VERSION "honda_bosch_a_radar -- 16-slot Bosch-A object bank (16 CAN-visible object slots, each a 4-frame main burst f0..f3 + one synchronized fine-angular companion frame). Hand-written (NOT generated by the opendbc generator pipeline). RANGE/AZIMUTH scaled companions are documentation-only; RadarInterface recomputes the physical values from RAW signals. f3 contains the two angular object bounds plus one matched edge-uncertainty magnitude; the companion frame contains the second matched edge-uncertainty magnitude and one still-unresolved auxiliary parameter. FRAME_IDX / LIFECYCLE_RAW are intentionally not named COUNTER."

NS_ :

BS_:

BU_: RADAR XXX

BO_ 640 BOSCH_A_S00_F0: 8 RADAR
 SG_ STATUS : 15|4@0+ (1,0) [0|15] "" XXX
 SG_ FRAME_IDX : 27|4@0+ (1,0) [0|15] "" XXX
 SG_ RANGE_RAW : 23|12@0+ (1,0) [0|4095] "" XXX
 SG_ RANGE : 23|12@0+ (0.05712,-3.0) [-3.0|231.7965] "m" XXX
 SG_ AZIMUTH_RAW : 39|11@0+ (1,0) [0|2047] "" XXX
 SG_ AZIMUTH_RAD : 39|11@0+ (0.00048828125,-0.5) [-0.5|0.49951171875] "rad" XXX
 SG_ AZIMUTH_DEG : 39|11@0+ (0.0279764548403722,-28.6478897565412) [-28.6478897565412|28.6199133017008] "deg" XXX

BO_ 641 BOSCH_A_S00_F1: 8 RADAR
 SG_ FRAME_IDX : 28|4@0+ (1,0) [0|15] "" XXX

BO_ 642 BOSCH_A_S00_F2: 8 RADAR
 SG_ FRAME_IDX : 11|4@0+ (1,0) [0|15] "" XXX
 SG_ LIFECYCLE_RAW : 7|12@0+ (1,0) [0|4095] "" XXX

BO_ 643 BOSCH_A_S00_F3: 8 RADAR
 SG_ AZIMUTH_EDGE_A_RAW : 7|11@0+ (1,0) [0|2047] "" XXX
 SG_ AZIMUTH_EDGE_A_RAD : 7|11@0+ (0.00048828125,-0.5) [-0.5|0.49951171875] "rad" XXX
 SG_ FRAME_IDX : 12|4@0+ (1,0) [0|15] "" XXX
 SG_ AZIMUTH_EDGE_B_RAW : 23|11@0+ (1,0) [0|2047] "" XXX
 SG_ AZIMUTH_EDGE_B_RAD : 23|11@0+ (0.00048828125,-0.5) [-0.5|0.49951171875] "rad" XXX
 SG_ AZIMUTH_EDGE_SIGMA_A_RAW : 39|10@0+ (1,0) [0|1023] "" XXX
 SG_ TRACK_ID : 55|8@0+ (1,0) [0|255] "" XXX

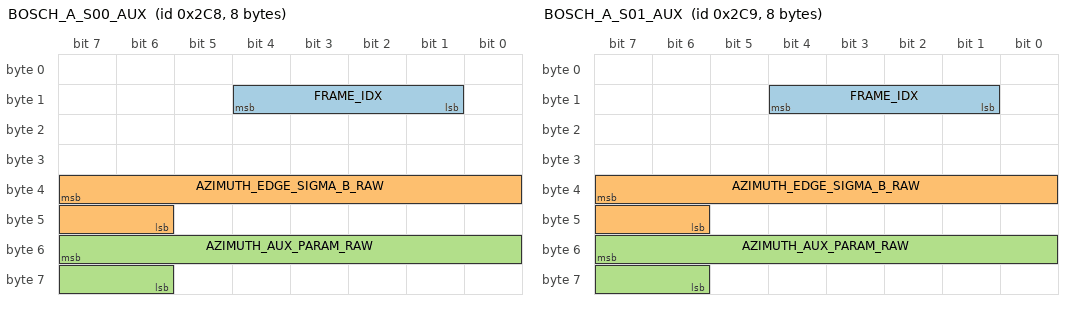
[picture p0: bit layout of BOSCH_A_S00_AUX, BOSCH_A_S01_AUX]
BO_ 712 BOSCH_A_S00_AUX: 8 RADAR
 SG_ FRAME_IDX : 12|4@0+ (1,0) [0|15] "" XXX
 SG_ AZIMUTH_EDGE_SIGMA_B_RAW : 39|10@0+ (1,0) [0|1023] "" XXX
 SG_ AZIMUTH_AUX_PARAM_RAW : 55|10@0+ (1,0) [0|1023] "" XXX

BO_ 644 BOSCH_A_S01_F0: 8 RADAR
 SG_ STATUS : 15|4@0+ (1,0) [0|15] "" XXX
 SG_ FRAME_IDX : 27|4@0+ (1,0) [0|15] "" XXX
 SG_ RANGE_RAW : 23|12@0+ (1,0) [0|4095] "" XXX
 SG_ RANGE : 23|12@0+ (0.05712,-3.0) [-3.0|231.7965] "m" XXX
 SG_ AZIMUTH_RAW : 39|11@0+ (1,0) [0|2047] "" XXX
 SG_ AZIMUTH_RAD : 39|11@0+ (0.00048828125,-0.5) [-0.5|0.49951171875] "rad" XXX
 SG_ AZIMUTH_DEG : 39|11@0+ (0.0279764548403722,-28.6478897565412) [-28.6478897565412|28.6199133017008] "deg" XXX

BO_ 645 BOSCH_A_S01_F1: 8 RADAR
 SG_ FRAME_IDX : 28|4@0+ (1,0) [0|15] "" XXX

BO_ 646 BOSCH_A_S01_F2: 8 RADAR
 SG_ FRAME_IDX : 11|4@0+ (1,0) [0|15] "" XXX
 SG_ LIFECYCLE_RAW : 7|12@0+ (1,0) [0|4095] "" XXX

BO_ 647 BOSCH_A_S01_F3: 8 RADAR
 SG_ AZIMUTH_EDGE_A_RAW : 7|11@0+ (1,0) [0|2047] "" XXX
 SG_ AZIMUTH_EDGE_A_RAD : 7|11@0+ (0.00048828125,-0.5) [-0.5|0.49951171875] "rad" XXX
 SG_ FRAME_IDX : 12|4@0+ (1,0) [0|15] "" XXX
 SG_ AZIMUTH_EDGE_B_RAW : 23|11@0+ (1,0) [0|2047] "" XXX
 SG_ AZIMUTH_EDGE_B_RAD : 23|11@0+ (0.00048828125,-0.5) [-0.5|0.49951171875] "rad" XXX
 SG_ AZIMUTH_EDGE_SIGMA_A_RAW : 39|10@0+ (1,0) [0|1023] "" XXX
 SG_ TRACK_ID : 55|8@0+ (1,0) [0|255] "" XXX

BO_ 713 BOSCH_A_S01_AUX: 8 RADAR
 SG_ FRAME_IDX : 12|4@0+ (1,0) [0|15] "" XXX
 SG_ AZIMUTH_EDGE_SIGMA_B_RAW : 39|10@0+ (1,0) [0|1023] "" XXX
 SG_ AZIMUTH_AUX_PARAM_RAW : 55|10@0+ (1,0) [0|1023] "" XXX

BO_ 648 BOSCH_A_S02_F0: 8 RADAR
 SG_ STATUS : 15|4@0+ (1,0) [0|15] "" XXX
 SG_ FRAME_IDX : 27|4@0+ (1,0) [0|15] "" XXX
 SG_ RANGE_RAW : 23|12@0+ (1,0) [0|4095] "" XXX
 SG_ RANGE : 23|12@0+ (0.05712,-3.0) [-3.0|231.7965] "m" XXX
 SG_ AZIMUTH_RAW : 39|11@0+ (1,0) [0|2047] "" XXX
 SG_ AZIMUTH_RAD : 39|11@0+ (0.00048828125,-0.5) [-0.5|0.49951171875] "rad" XXX
 SG_ AZIMUTH_DEG : 39|11@0+ (0.0279764548403722,-28.6478897565412) [-28.6478897565412|28.6199133017008] "deg" XXX

BO_ 649 BOSCH_A_S02_F1: 8 RADAR
 SG_ FRAME_IDX : 28|4@0+ (1,0) [0|15] "" XXX

BO_ 650 BOSCH_A_S02_F2: 8 RADAR
 SG_ FRAME_IDX : 11|4@0+ (1,0) [0|15] "" XXX
 SG_ LIFECYCLE_RAW : 7|12@0+ (1,0) [0|4095] "" XXX

BO_ 651 BOSCH_A_S02_F3: 8 RADAR
 SG_ AZIMUTH_EDGE_A_RAW : 7|11@0+ (1,0) [0|2047] "" XXX
 SG_ AZIMUTH_EDGE_A_RAD : 7|11@0+ (0.00048828125,-0.5) [-0.5|0.49951171875] "rad" XXX
 SG_ FRAME_IDX : 12|4@0+ (1,0) [0|15] "" XXX
 SG_ AZIMUTH_EDGE_B_RAW : 23|11@0+ (1,0) [0|2047] "" XXX
 SG_ AZIMUTH_EDGE_B_RAD : 23|11@0+ (0.00048828125,-0.5) [-0.5|0.49951171875] "rad" XXX
 SG_ AZIMUTH_EDGE_SIGMA_A_RAW : 39|10@0+ (1,0) [0|1023] "" XXX
 SG_ TRACK_ID : 55|8@0+ (1,0) [0|255] "" XXX

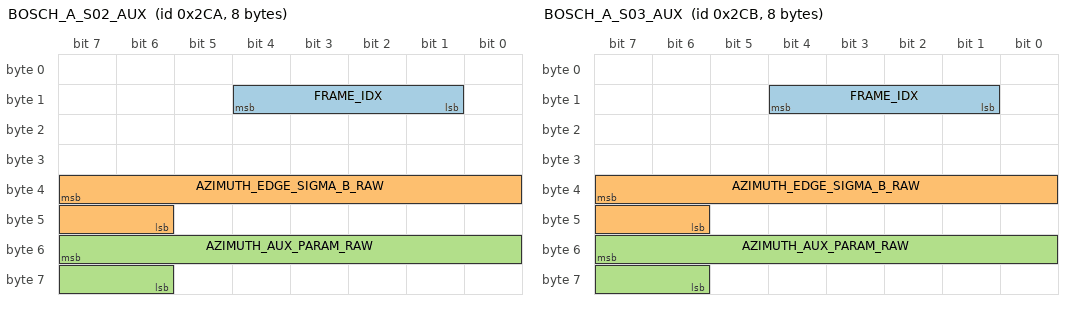
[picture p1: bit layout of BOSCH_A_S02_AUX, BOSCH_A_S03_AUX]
BO_ 714 BOSCH_A_S02_AUX: 8 RADAR
 SG_ FRAME_IDX : 12|4@0+ (1,0) [0|15] "" XXX
 SG_ AZIMUTH_EDGE_SIGMA_B_RAW : 39|10@0+ (1,0) [0|1023] "" XXX
 SG_ AZIMUTH_AUX_PARAM_RAW : 55|10@0+ (1,0) [0|1023] "" XXX

BO_ 652 BOSCH_A_S03_F0: 8 RADAR
 SG_ STATUS : 15|4@0+ (1,0) [0|15] "" XXX
 SG_ FRAME_IDX : 27|4@0+ (1,0) [0|15] "" XXX
 SG_ RANGE_RAW : 23|12@0+ (1,0) [0|4095] "" XXX
 SG_ RANGE : 23|12@0+ (0.05712,-3.0) [-3.0|231.7965] "m" XXX
 SG_ AZIMUTH_RAW : 39|11@0+ (1,0) [0|2047] "" XXX
 SG_ AZIMUTH_RAD : 39|11@0+ (0.00048828125,-0.5) [-0.5|0.49951171875] "rad" XXX
 SG_ AZIMUTH_DEG : 39|11@0+ (0.0279764548403722,-28.6478897565412) [-28.6478897565412|28.6199133017008] "deg" XXX

BO_ 653 BOSCH_A_S03_F1: 8 RADAR
 SG_ FRAME_IDX : 28|4@0+ (1,0) [0|15] "" XXX

BO_ 654 BOSCH_A_S03_F2: 8 RADAR
 SG_ FRAME_IDX : 11|4@0+ (1,0) [0|15] "" XXX
 SG_ LIFECYCLE_RAW : 7|12@0+ (1,0) [0|4095] "" XXX

BO_ 655 BOSCH_A_S03_F3: 8 RADAR
 SG_ AZIMUTH_EDGE_A_RAW : 7|11@0+ (1,0) [0|2047] "" XXX
 SG_ AZIMUTH_EDGE_A_RAD : 7|11@0+ (0.00048828125,-0.5) [-0.5|0.49951171875] "rad" XXX
 SG_ FRAME_IDX : 12|4@0+ (1,0) [0|15] "" XXX
 SG_ AZIMUTH_EDGE_B_RAW : 23|11@0+ (1,0) [0|2047] "" XXX
 SG_ AZIMUTH_EDGE_B_RAD : 23|11@0+ (0.00048828125,-0.5) [-0.5|0.49951171875] "rad" XXX
 SG_ AZIMUTH_EDGE_SIGMA_A_RAW : 39|10@0+ (1,0) [0|1023] "" XXX
 SG_ TRACK_ID : 55|8@0+ (1,0) [0|255] "" XXX

BO_ 715 BOSCH_A_S03_AUX: 8 RADAR
 SG_ FRAME_IDX : 12|4@0+ (1,0) [0|15] "" XXX
 SG_ AZIMUTH_EDGE_SIGMA_B_RAW : 39|10@0+ (1,0) [0|1023] "" XXX
 SG_ AZIMUTH_AUX_PARAM_RAW : 55|10@0+ (1,0) [0|1023] "" XXX

BO_ 720 BOSCH_A_S04_F0: 8 RADAR
 SG_ STATUS : 15|4@0+ (1,0) [0|15] "" XXX
 SG_ FRAME_IDX : 27|4@0+ (1,0) [0|15] "" XXX
 SG_ RANGE_RAW : 23|12@0+ (1,0) [0|4095] "" XXX
 SG_ RANGE : 23|12@0+ (0.05712,-3.0) [-3.0|231.7965] "m" XXX
 SG_ AZIMUTH_RAW : 39|11@0+ (1,0) [0|2047] "" XXX
 SG_ AZIMUTH_RAD : 39|11@0+ (0.00048828125,-0.5) [-0.5|0.49951171875] "rad" XXX
 SG_ AZIMUTH_DEG : 39|11@0+ (0.0279764548403722,-28.6478897565412) [-28.6478897565412|28.6199133017008] "deg" XXX

BO_ 721 BOSCH_A_S04_F1: 8 RADAR
 SG_ FRAME_IDX : 28|4@0+ (1,0) [0|15] "" XXX

BO_ 722 BOSCH_A_S04_F2: 8 RADAR
 SG_ FRAME_IDX : 11|4@0+ (1,0) [0|15] "" XXX
 SG_ LIFECYCLE_RAW : 7|12@0+ (1,0) [0|4095] "" XXX

BO_ 723 BOSCH_A_S04_F3: 8 RADAR
 SG_ AZIMUTH_EDGE_A_RAW : 7|11@0+ (1,0) [0|2047] "" XXX
 SG_ AZIMUTH_EDGE_A_RAD : 7|11@0+ (0.00048828125,-0.5) [-0.5|0.49951171875] "rad" XXX
 SG_ FRAME_IDX : 12|4@0+ (1,0) [0|15] "" XXX
 SG_ AZIMUTH_EDGE_B_RAW : 23|11@0+ (1,0) [0|2047] "" XXX
 SG_ AZIMUTH_EDGE_B_RAD : 23|11@0+ (0.00048828125,-0.5) [-0.5|0.49951171875] "rad" XXX
 SG_ AZIMUTH_EDGE_SIGMA_A_RAW : 39|10@0+ (1,0) [0|1023] "" XXX
 SG_ TRACK_ID : 55|8@0+ (1,0) [0|255] "" XXX

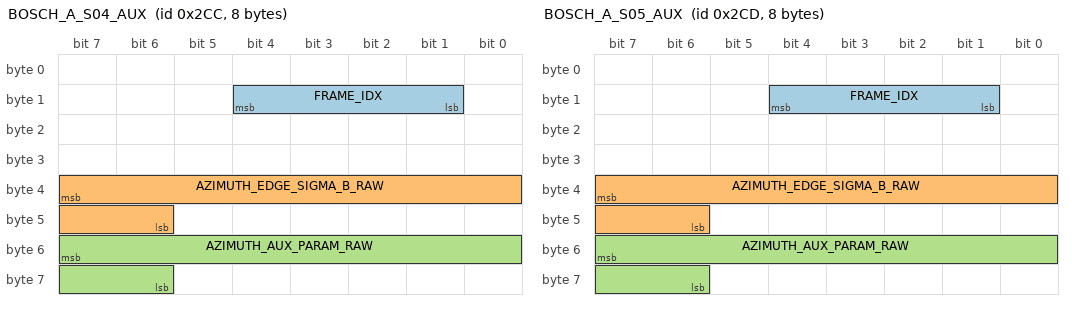
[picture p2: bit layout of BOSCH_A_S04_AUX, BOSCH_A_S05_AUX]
BO_ 716 BOSCH_A_S04_AUX: 8 RADAR
 SG_ FRAME_IDX : 12|4@0+ (1,0) [0|15] "" XXX
 SG_ AZIMUTH_EDGE_SIGMA_B_RAW : 39|10@0+ (1,0) [0|1023] "" XXX
 SG_ AZIMUTH_AUX_PARAM_RAW : 55|10@0+ (1,0) [0|1023] "" XXX

BO_ 724 BOSCH_A_S05_F0: 8 RADAR
 SG_ STATUS : 15|4@0+ (1,0) [0|15] "" XXX
 SG_ FRAME_IDX : 27|4@0+ (1,0) [0|15] "" XXX
 SG_ RANGE_RAW : 23|12@0+ (1,0) [0|4095] "" XXX
 SG_ RANGE : 23|12@0+ (0.05712,-3.0) [-3.0|231.7965] "m" XXX
 SG_ AZIMUTH_RAW : 39|11@0+ (1,0) [0|2047] "" XXX
 SG_ AZIMUTH_RAD : 39|11@0+ (0.00048828125,-0.5) [-0.5|0.49951171875] "rad" XXX
 SG_ AZIMUTH_DEG : 39|11@0+ (0.0279764548403722,-28.6478897565412) [-28.6478897565412|28.6199133017008] "deg" XXX

BO_ 725 BOSCH_A_S05_F1: 8 RADAR
 SG_ FRAME_IDX : 28|4@0+ (1,0) [0|15] "" XXX

BO_ 726 BOSCH_A_S05_F2: 8 RADAR
 SG_ FRAME_IDX : 11|4@0+ (1,0) [0|15] "" XXX
 SG_ LIFECYCLE_RAW : 7|12@0+ (1,0) [0|4095] "" XXX

BO_ 727 BOSCH_A_S05_F3: 8 RADAR
 SG_ AZIMUTH_EDGE_A_RAW : 7|11@0+ (1,0) [0|2047] "" XXX
 SG_ AZIMUTH_EDGE_A_RAD : 7|11@0+ (0.00048828125,-0.5) [-0.5|0.49951171875] "rad" XXX
 SG_ FRAME_IDX : 12|4@0+ (1,0) [0|15] "" XXX
 SG_ AZIMUTH_EDGE_B_RAW : 23|11@0+ (1,0) [0|2047] "" XXX
 SG_ AZIMUTH_EDGE_B_RAD : 23|11@0+ (0.00048828125,-0.5) [-0.5|0.49951171875] "rad" XXX
 SG_ AZIMUTH_EDGE_SIGMA_A_RAW : 39|10@0+ (1,0) [0|1023] "" XXX
 SG_ TRACK_ID : 55|8@0+ (1,0) [0|255] "" XXX

BO_ 717 BOSCH_A_S05_AUX: 8 RADAR
 SG_ FRAME_IDX : 12|4@0+ (1,0) [0|15] "" XXX
 SG_ AZIMUTH_EDGE_SIGMA_B_RAW : 39|10@0+ (1,0) [0|1023] "" XXX
 SG_ AZIMUTH_AUX_PARAM_RAW : 55|10@0+ (1,0) [0|1023] "" XXX

BO_ 728 BOSCH_A_S06_F0: 8 RADAR
 SG_ STATUS : 15|4@0+ (1,0) [0|15] "" XXX
 SG_ FRAME_IDX : 27|4@0+ (1,0) [0|15] "" XXX
 SG_ RANGE_RAW : 23|12@0+ (1,0) [0|4095] "" XXX
 SG_ RANGE : 23|12@0+ (0.05712,-3.0) [-3.0|231.7965] "m" XXX
 SG_ AZIMUTH_RAW : 39|11@0+ (1,0) [0|2047] "" XXX
 SG_ AZIMUTH_RAD : 39|11@0+ (0.00048828125,-0.5) [-0.5|0.49951171875] "rad" XXX
 SG_ AZIMUTH_DEG : 39|11@0+ (0.0279764548403722,-28.6478897565412) [-28.6478897565412|28.6199133017008] "deg" XXX

BO_ 729 BOSCH_A_S06_F1: 8 RADAR
 SG_ FRAME_IDX : 28|4@0+ (1,0) [0|15] "" XXX

BO_ 730 BOSCH_A_S06_F2: 8 RADAR
 SG_ FRAME_IDX : 11|4@0+ (1,0) [0|15] "" XXX
 SG_ LIFECYCLE_RAW : 7|12@0+ (1,0) [0|4095] "" XXX

BO_ 731 BOSCH_A_S06_F3: 8 RADAR
 SG_ AZIMUTH_EDGE_A_RAW : 7|11@0+ (1,0) [0|2047] "" XXX
 SG_ AZIMUTH_EDGE_A_RAD : 7|11@0+ (0.00048828125,-0.5) [-0.5|0.49951171875] "rad" XXX
 SG_ FRAME_IDX : 12|4@0+ (1,0) [0|15] "" XXX
 SG_ AZIMUTH_EDGE_B_RAW : 23|11@0+ (1,0) [0|2047] "" XXX
 SG_ AZIMUTH_EDGE_B_RAD : 23|11@0+ (0.00048828125,-0.5) [-0.5|0.49951171875] "rad" XXX
 SG_ AZIMUTH_EDGE_SIGMA_A_RAW : 39|10@0+ (1,0) [0|1023] "" XXX
 SG_ TRACK_ID : 55|8@0+ (1,0) [0|255] "" XXX

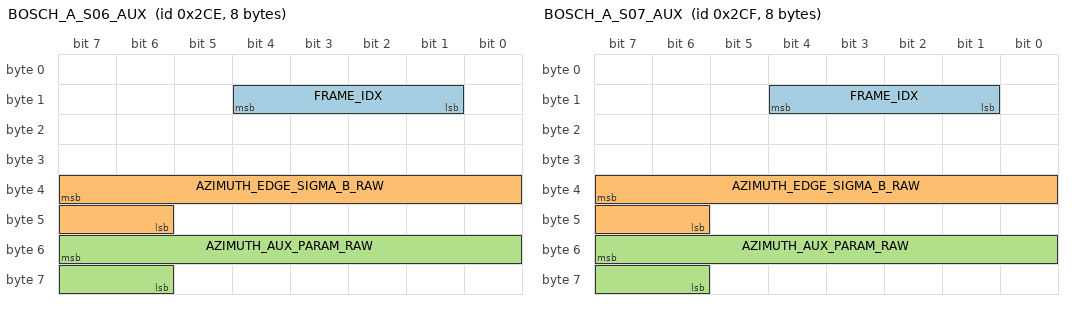
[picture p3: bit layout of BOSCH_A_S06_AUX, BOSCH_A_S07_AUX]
BO_ 718 BOSCH_A_S06_AUX: 8 RADAR
 SG_ FRAME_IDX : 12|4@0+ (1,0) [0|15] "" XXX
 SG_ AZIMUTH_EDGE_SIGMA_B_RAW : 39|10@0+ (1,0) [0|1023] "" XXX
 SG_ AZIMUTH_AUX_PARAM_RAW : 55|10@0+ (1,0) [0|1023] "" XXX

BO_ 732 BOSCH_A_S07_F0: 8 RADAR
 SG_ STATUS : 15|4@0+ (1,0) [0|15] "" XXX
 SG_ FRAME_IDX : 27|4@0+ (1,0) [0|15] "" XXX
 SG_ RANGE_RAW : 23|12@0+ (1,0) [0|4095] "" XXX
 SG_ RANGE : 23|12@0+ (0.05712,-3.0) [-3.0|231.7965] "m" XXX
 SG_ AZIMUTH_RAW : 39|11@0+ (1,0) [0|2047] "" XXX
 SG_ AZIMUTH_RAD : 39|11@0+ (0.00048828125,-0.5) [-0.5|0.49951171875] "rad" XXX
 SG_ AZIMUTH_DEG : 39|11@0+ (0.0279764548403722,-28.6478897565412) [-28.6478897565412|28.6199133017008] "deg" XXX

BO_ 733 BOSCH_A_S07_F1: 8 RADAR
 SG_ FRAME_IDX : 28|4@0+ (1,0) [0|15] "" XXX

BO_ 734 BOSCH_A_S07_F2: 8 RADAR
 SG_ FRAME_IDX : 11|4@0+ (1,0) [0|15] "" XXX
 SG_ LIFECYCLE_RAW : 7|12@0+ (1,0) [0|4095] "" XXX

BO_ 735 BOSCH_A_S07_F3: 8 RADAR
 SG_ AZIMUTH_EDGE_A_RAW : 7|11@0+ (1,0) [0|2047] "" XXX
 SG_ AZIMUTH_EDGE_A_RAD : 7|11@0+ (0.00048828125,-0.5) [-0.5|0.49951171875] "rad" XXX
 SG_ FRAME_IDX : 12|4@0+ (1,0) [0|15] "" XXX
 SG_ AZIMUTH_EDGE_B_RAW : 23|11@0+ (1,0) [0|2047] "" XXX
 SG_ AZIMUTH_EDGE_B_RAD : 23|11@0+ (0.00048828125,-0.5) [-0.5|0.49951171875] "rad" XXX
 SG_ AZIMUTH_EDGE_SIGMA_A_RAW : 39|10@0+ (1,0) [0|1023] "" XXX
 SG_ TRACK_ID : 55|8@0+ (1,0) [0|255] "" XXX

BO_ 719 BOSCH_A_S07_AUX: 8 RADAR
 SG_ FRAME_IDX : 12|4@0+ (1,0) [0|15] "" XXX
 SG_ AZIMUTH_EDGE_SIGMA_B_RAW : 39|10@0+ (1,0) [0|1023] "" XXX
 SG_ AZIMUTH_AUX_PARAM_RAW : 55|10@0+ (1,0) [0|1023] "" XXX

BO_ 736 BOSCH_A_S08_F0: 8 RADAR
 SG_ STATUS : 15|4@0+ (1,0) [0|15] "" XXX
 SG_ FRAME_IDX : 27|4@0+ (1,0) [0|15] "" XXX
 SG_ RANGE_RAW : 23|12@0+ (1,0) [0|4095] "" XXX
 SG_ RANGE : 23|12@0+ (0.05712,-3.0) [-3.0|231.7965] "m" XXX
 SG_ AZIMUTH_RAW : 39|11@0+ (1,0) [0|2047] "" XXX
 SG_ AZIMUTH_RAD : 39|11@0+ (0.00048828125,-0.5) [-0.5|0.49951171875] "rad" XXX
 SG_ AZIMUTH_DEG : 39|11@0+ (0.0279764548403722,-28.6478897565412) [-28.6478897565412|28.6199133017008] "deg" XXX

BO_ 737 BOSCH_A_S08_F1: 8 RADAR
 SG_ FRAME_IDX : 28|4@0+ (1,0) [0|15] "" XXX

BO_ 738 BOSCH_A_S08_F2: 8 RADAR
 SG_ FRAME_IDX : 11|4@0+ (1,0) [0|15] "" XXX
 SG_ LIFECYCLE_RAW : 7|12@0+ (1,0) [0|4095] "" XXX

BO_ 739 BOSCH_A_S08_F3: 8 RADAR
 SG_ AZIMUTH_EDGE_A_RAW : 7|11@0+ (1,0) [0|2047] "" XXX
 SG_ AZIMUTH_EDGE_A_RAD : 7|11@0+ (0.00048828125,-0.5) [-0.5|0.49951171875] "rad" XXX
 SG_ FRAME_IDX : 12|4@0+ (1,0) [0|15] "" XXX
 SG_ AZIMUTH_EDGE_B_RAW : 23|11@0+ (1,0) [0|2047] "" XXX
 SG_ AZIMUTH_EDGE_B_RAD : 23|11@0+ (0.00048828125,-0.5) [-0.5|0.49951171875] "rad" XXX
 SG_ AZIMUTH_EDGE_SIGMA_A_RAW : 39|10@0+ (1,0) [0|1023] "" XXX
 SG_ TRACK_ID : 55|8@0+ (1,0) [0|255] "" XXX

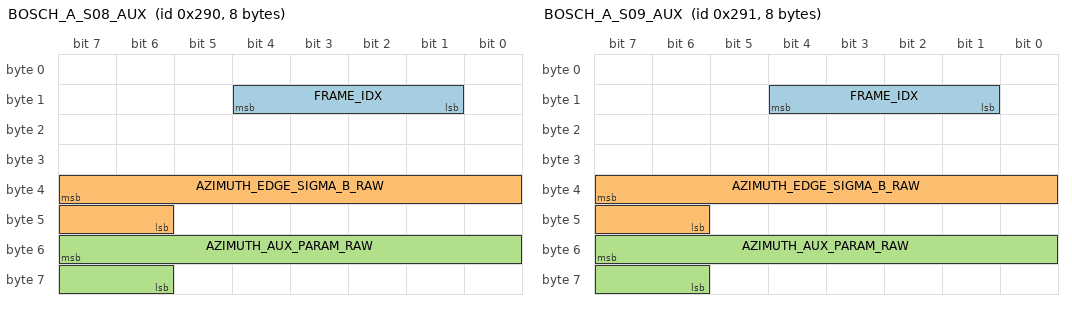
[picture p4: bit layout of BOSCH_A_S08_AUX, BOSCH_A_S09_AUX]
BO_ 656 BOSCH_A_S08_AUX: 8 RADAR
 SG_ FRAME_IDX : 12|4@0+ (1,0) [0|15] "" XXX
 SG_ AZIMUTH_EDGE_SIGMA_B_RAW : 39|10@0+ (1,0) [0|1023] "" XXX
 SG_ AZIMUTH_AUX_PARAM_RAW : 55|10@0+ (1,0) [0|1023] "" XXX

BO_ 740 BOSCH_A_S09_F0: 8 RADAR
 SG_ STATUS : 15|4@0+ (1,0) [0|15] "" XXX
 SG_ FRAME_IDX : 27|4@0+ (1,0) [0|15] "" XXX
 SG_ RANGE_RAW : 23|12@0+ (1,0) [0|4095] "" XXX
 SG_ RANGE : 23|12@0+ (0.05712,-3.0) [-3.0|231.7965] "m" XXX
 SG_ AZIMUTH_RAW : 39|11@0+ (1,0) [0|2047] "" XXX
 SG_ AZIMUTH_RAD : 39|11@0+ (0.00048828125,-0.5) [-0.5|0.49951171875] "rad" XXX
 SG_ AZIMUTH_DEG : 39|11@0+ (0.0279764548403722,-28.6478897565412) [-28.6478897565412|28.6199133017008] "deg" XXX

BO_ 741 BOSCH_A_S09_F1: 8 RADAR
 SG_ FRAME_IDX : 28|4@0+ (1,0) [0|15] "" XXX

BO_ 742 BOSCH_A_S09_F2: 8 RADAR
 SG_ FRAME_IDX : 11|4@0+ (1,0) [0|15] "" XXX
 SG_ LIFECYCLE_RAW : 7|12@0+ (1,0) [0|4095] "" XXX

BO_ 743 BOSCH_A_S09_F3: 8 RADAR
 SG_ AZIMUTH_EDGE_A_RAW : 7|11@0+ (1,0) [0|2047] "" XXX
 SG_ AZIMUTH_EDGE_A_RAD : 7|11@0+ (0.00048828125,-0.5) [-0.5|0.49951171875] "rad" XXX
 SG_ FRAME_IDX : 12|4@0+ (1,0) [0|15] "" XXX
 SG_ AZIMUTH_EDGE_B_RAW : 23|11@0+ (1,0) [0|2047] "" XXX
 SG_ AZIMUTH_EDGE_B_RAD : 23|11@0+ (0.00048828125,-0.5) [-0.5|0.49951171875] "rad" XXX
 SG_ AZIMUTH_EDGE_SIGMA_A_RAW : 39|10@0+ (1,0) [0|1023] "" XXX
 SG_ TRACK_ID : 55|8@0+ (1,0) [0|255] "" XXX

BO_ 657 BOSCH_A_S09_AUX: 8 RADAR
 SG_ FRAME_IDX : 12|4@0+ (1,0) [0|15] "" XXX
 SG_ AZIMUTH_EDGE_SIGMA_B_RAW : 39|10@0+ (1,0) [0|1023] "" XXX
 SG_ AZIMUTH_AUX_PARAM_RAW : 55|10@0+ (1,0) [0|1023] "" XXX

BO_ 744 BOSCH_A_S10_F0: 8 RADAR
 SG_ STATUS : 15|4@0+ (1,0) [0|15] "" XXX
 SG_ FRAME_IDX : 27|4@0+ (1,0) [0|15] "" XXX
 SG_ RANGE_RAW : 23|12@0+ (1,0) [0|4095] "" XXX
 SG_ RANGE : 23|12@0+ (0.05712,-3.0) [-3.0|231.7965] "m" XXX
 SG_ AZIMUTH_RAW : 39|11@0+ (1,0) [0|2047] "" XXX
 SG_ AZIMUTH_RAD : 39|11@0+ (0.00048828125,-0.5) [-0.5|0.49951171875] "rad" XXX
 SG_ AZIMUTH_DEG : 39|11@0+ (0.0279764548403722,-28.6478897565412) [-28.6478897565412|28.6199133017008] "deg" XXX

BO_ 745 BOSCH_A_S10_F1: 8 RADAR
 SG_ FRAME_IDX : 28|4@0+ (1,0) [0|15] "" XXX

BO_ 746 BOSCH_A_S10_F2: 8 RADAR
 SG_ FRAME_IDX : 11|4@0+ (1,0) [0|15] "" XXX
 SG_ LIFECYCLE_RAW : 7|12@0+ (1,0) [0|4095] "" XXX

BO_ 747 BOSCH_A_S10_F3: 8 RADAR
 SG_ AZIMUTH_EDGE_A_RAW : 7|11@0+ (1,0) [0|2047] "" XXX
 SG_ AZIMUTH_EDGE_A_RAD : 7|11@0+ (0.00048828125,-0.5) [-0.5|0.49951171875] "rad" XXX
 SG_ FRAME_IDX : 12|4@0+ (1,0) [0|15] "" XXX
 SG_ AZIMUTH_EDGE_B_RAW : 23|11@0+ (1,0) [0|2047] "" XXX
 SG_ AZIMUTH_EDGE_B_RAD : 23|11@0+ (0.00048828125,-0.5) [-0.5|0.49951171875] "rad" XXX
 SG_ AZIMUTH_EDGE_SIGMA_A_RAW : 39|10@0+ (1,0) [0|1023] "" XXX
 SG_ TRACK_ID : 55|8@0+ (1,0) [0|255] "" XXX

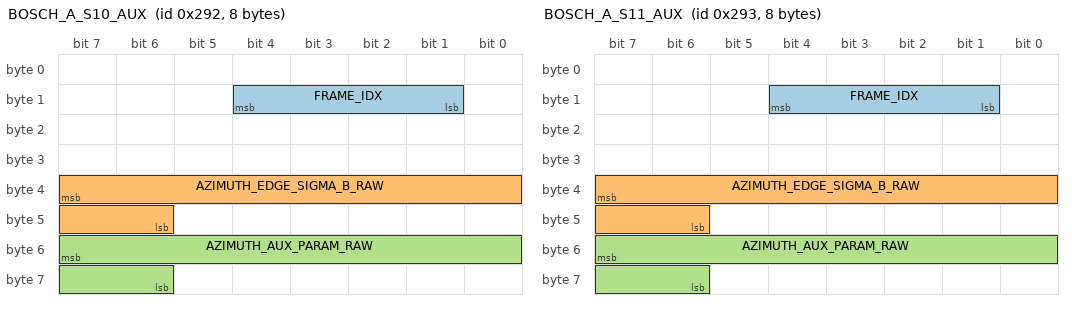
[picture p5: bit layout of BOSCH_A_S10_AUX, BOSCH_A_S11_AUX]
BO_ 658 BOSCH_A_S10_AUX: 8 RADAR
 SG_ FRAME_IDX : 12|4@0+ (1,0) [0|15] "" XXX
 SG_ AZIMUTH_EDGE_SIGMA_B_RAW : 39|10@0+ (1,0) [0|1023] "" XXX
 SG_ AZIMUTH_AUX_PARAM_RAW : 55|10@0+ (1,0) [0|1023] "" XXX

BO_ 748 BOSCH_A_S11_F0: 8 RADAR
 SG_ STATUS : 15|4@0+ (1,0) [0|15] "" XXX
 SG_ FRAME_IDX : 27|4@0+ (1,0) [0|15] "" XXX
 SG_ RANGE_RAW : 23|12@0+ (1,0) [0|4095] "" XXX
 SG_ RANGE : 23|12@0+ (0.05712,-3.0) [-3.0|231.7965] "m" XXX
 SG_ AZIMUTH_RAW : 39|11@0+ (1,0) [0|2047] "" XXX
 SG_ AZIMUTH_RAD : 39|11@0+ (0.00048828125,-0.5) [-0.5|0.49951171875] "rad" XXX
 SG_ AZIMUTH_DEG : 39|11@0+ (0.0279764548403722,-28.6478897565412) [-28.6478897565412|28.6199133017008] "deg" XXX

BO_ 749 BOSCH_A_S11_F1: 8 RADAR
 SG_ FRAME_IDX : 28|4@0+ (1,0) [0|15] "" XXX

BO_ 750 BOSCH_A_S11_F2: 8 RADAR
 SG_ FRAME_IDX : 11|4@0+ (1,0) [0|15] "" XXX
 SG_ LIFECYCLE_RAW : 7|12@0+ (1,0) [0|4095] "" XXX

BO_ 751 BOSCH_A_S11_F3: 8 RADAR
 SG_ AZIMUTH_EDGE_A_RAW : 7|11@0+ (1,0) [0|2047] "" XXX
 SG_ AZIMUTH_EDGE_A_RAD : 7|11@0+ (0.00048828125,-0.5) [-0.5|0.49951171875] "rad" XXX
 SG_ FRAME_IDX : 12|4@0+ (1,0) [0|15] "" XXX
 SG_ AZIMUTH_EDGE_B_RAW : 23|11@0+ (1,0) [0|2047] "" XXX
 SG_ AZIMUTH_EDGE_B_RAD : 23|11@0+ (0.00048828125,-0.5) [-0.5|0.49951171875] "rad" XXX
 SG_ AZIMUTH_EDGE_SIGMA_A_RAW : 39|10@0+ (1,0) [0|1023] "" XXX
 SG_ TRACK_ID : 55|8@0+ (1,0) [0|255] "" XXX

BO_ 659 BOSCH_A_S11_AUX: 8 RADAR
 SG_ FRAME_IDX : 12|4@0+ (1,0) [0|15] "" XXX
 SG_ AZIMUTH_EDGE_SIGMA_B_RAW : 39|10@0+ (1,0) [0|1023] "" XXX
 SG_ AZIMUTH_AUX_PARAM_RAW : 55|10@0+ (1,0) [0|1023] "" XXX

BO_ 752 BOSCH_A_S12_F0: 8 RADAR
 SG_ STATUS : 15|4@0+ (1,0) [0|15] "" XXX
 SG_ FRAME_IDX : 27|4@0+ (1,0) [0|15] "" XXX
 SG_ RANGE_RAW : 23|12@0+ (1,0) [0|4095] "" XXX
 SG_ RANGE : 23|12@0+ (0.05712,-3.0) [-3.0|231.7965] "m" XXX
 SG_ AZIMUTH_RAW : 39|11@0+ (1,0) [0|2047] "" XXX
 SG_ AZIMUTH_RAD : 39|11@0+ (0.00048828125,-0.5) [-0.5|0.49951171875] "rad" XXX
 SG_ AZIMUTH_DEG : 39|11@0+ (0.0279764548403722,-28.6478897565412) [-28.6478897565412|28.6199133017008] "deg" XXX

BO_ 753 BOSCH_A_S12_F1: 8 RADAR
 SG_ FRAME_IDX : 28|4@0+ (1,0) [0|15] "" XXX

BO_ 754 BOSCH_A_S12_F2: 8 RADAR
 SG_ FRAME_IDX : 11|4@0+ (1,0) [0|15] "" XXX
 SG_ LIFECYCLE_RAW : 7|12@0+ (1,0) [0|4095] "" XXX

BO_ 755 BOSCH_A_S12_F3: 8 RADAR
 SG_ AZIMUTH_EDGE_A_RAW : 7|11@0+ (1,0) [0|2047] "" XXX
 SG_ AZIMUTH_EDGE_A_RAD : 7|11@0+ (0.00048828125,-0.5) [-0.5|0.49951171875] "rad" XXX
 SG_ FRAME_IDX : 12|4@0+ (1,0) [0|15] "" XXX
 SG_ AZIMUTH_EDGE_B_RAW : 23|11@0+ (1,0) [0|2047] "" XXX
 SG_ AZIMUTH_EDGE_B_RAD : 23|11@0+ (0.00048828125,-0.5) [-0.5|0.49951171875] "rad" XXX
 SG_ AZIMUTH_EDGE_SIGMA_A_RAW : 39|10@0+ (1,0) [0|1023] "" XXX
 SG_ TRACK_ID : 55|8@0+ (1,0) [0|255] "" XXX

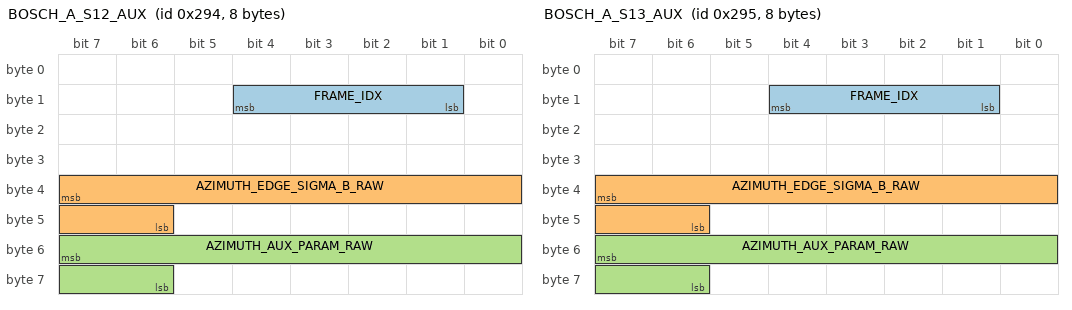
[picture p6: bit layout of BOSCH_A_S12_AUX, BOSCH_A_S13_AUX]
BO_ 660 BOSCH_A_S12_AUX: 8 RADAR
 SG_ FRAME_IDX : 12|4@0+ (1,0) [0|15] "" XXX
 SG_ AZIMUTH_EDGE_SIGMA_B_RAW : 39|10@0+ (1,0) [0|1023] "" XXX
 SG_ AZIMUTH_AUX_PARAM_RAW : 55|10@0+ (1,0) [0|1023] "" XXX

BO_ 756 BOSCH_A_S13_F0: 8 RADAR
 SG_ STATUS : 15|4@0+ (1,0) [0|15] "" XXX
 SG_ FRAME_IDX : 27|4@0+ (1,0) [0|15] "" XXX
 SG_ RANGE_RAW : 23|12@0+ (1,0) [0|4095] "" XXX
 SG_ RANGE : 23|12@0+ (0.05712,-3.0) [-3.0|231.7965] "m" XXX
 SG_ AZIMUTH_RAW : 39|11@0+ (1,0) [0|2047] "" XXX
 SG_ AZIMUTH_RAD : 39|11@0+ (0.00048828125,-0.5) [-0.5|0.49951171875] "rad" XXX
 SG_ AZIMUTH_DEG : 39|11@0+ (0.0279764548403722,-28.6478897565412) [-28.6478897565412|28.6199133017008] "deg" XXX

BO_ 757 BOSCH_A_S13_F1: 8 RADAR
 SG_ FRAME_IDX : 28|4@0+ (1,0) [0|15] "" XXX

BO_ 758 BOSCH_A_S13_F2: 8 RADAR
 SG_ FRAME_IDX : 11|4@0+ (1,0) [0|15] "" XXX
 SG_ LIFECYCLE_RAW : 7|12@0+ (1,0) [0|4095] "" XXX

BO_ 759 BOSCH_A_S13_F3: 8 RADAR
 SG_ AZIMUTH_EDGE_A_RAW : 7|11@0+ (1,0) [0|2047] "" XXX
 SG_ AZIMUTH_EDGE_A_RAD : 7|11@0+ (0.00048828125,-0.5) [-0.5|0.49951171875] "rad" XXX
 SG_ FRAME_IDX : 12|4@0+ (1,0) [0|15] "" XXX
 SG_ AZIMUTH_EDGE_B_RAW : 23|11@0+ (1,0) [0|2047] "" XXX
 SG_ AZIMUTH_EDGE_B_RAD : 23|11@0+ (0.00048828125,-0.5) [-0.5|0.49951171875] "rad" XXX
 SG_ AZIMUTH_EDGE_SIGMA_A_RAW : 39|10@0+ (1,0) [0|1023] "" XXX
 SG_ TRACK_ID : 55|8@0+ (1,0) [0|255] "" XXX

BO_ 661 BOSCH_A_S13_AUX: 8 RADAR
 SG_ FRAME_IDX : 12|4@0+ (1,0) [0|15] "" XXX
 SG_ AZIMUTH_EDGE_SIGMA_B_RAW : 39|10@0+ (1,0) [0|1023] "" XXX
 SG_ AZIMUTH_AUX_PARAM_RAW : 55|10@0+ (1,0) [0|1023] "" XXX

BO_ 760 BOSCH_A_S14_F0: 8 RADAR
 SG_ STATUS : 15|4@0+ (1,0) [0|15] "" XXX
 SG_ FRAME_IDX : 27|4@0+ (1,0) [0|15] "" XXX
 SG_ RANGE_RAW : 23|12@0+ (1,0) [0|4095] "" XXX
 SG_ RANGE : 23|12@0+ (0.05712,-3.0) [-3.0|231.7965] "m" XXX
 SG_ AZIMUTH_RAW : 39|11@0+ (1,0) [0|2047] "" XXX
 SG_ AZIMUTH_RAD : 39|11@0+ (0.00048828125,-0.5) [-0.5|0.49951171875] "rad" XXX
 SG_ AZIMUTH_DEG : 39|11@0+ (0.0279764548403722,-28.6478897565412) [-28.6478897565412|28.6199133017008] "deg" XXX

BO_ 761 BOSCH_A_S14_F1: 8 RADAR
 SG_ FRAME_IDX : 28|4@0+ (1,0) [0|15] "" XXX

BO_ 762 BOSCH_A_S14_F2: 8 RADAR
 SG_ FRAME_IDX : 11|4@0+ (1,0) [0|15] "" XXX
 SG_ LIFECYCLE_RAW : 7|12@0+ (1,0) [0|4095] "" XXX

BO_ 763 BOSCH_A_S14_F3: 8 RADAR
 SG_ AZIMUTH_EDGE_A_RAW : 7|11@0+ (1,0) [0|2047] "" XXX
 SG_ AZIMUTH_EDGE_A_RAD : 7|11@0+ (0.00048828125,-0.5) [-0.5|0.49951171875] "rad" XXX
 SG_ FRAME_IDX : 12|4@0+ (1,0) [0|15] "" XXX
 SG_ AZIMUTH_EDGE_B_RAW : 23|11@0+ (1,0) [0|2047] "" XXX
 SG_ AZIMUTH_EDGE_B_RAD : 23|11@0+ (0.00048828125,-0.5) [-0.5|0.49951171875] "rad" XXX
 SG_ AZIMUTH_EDGE_SIGMA_A_RAW : 39|10@0+ (1,0) [0|1023] "" XXX
 SG_ TRACK_ID : 55|8@0+ (1,0) [0|255] "" XXX

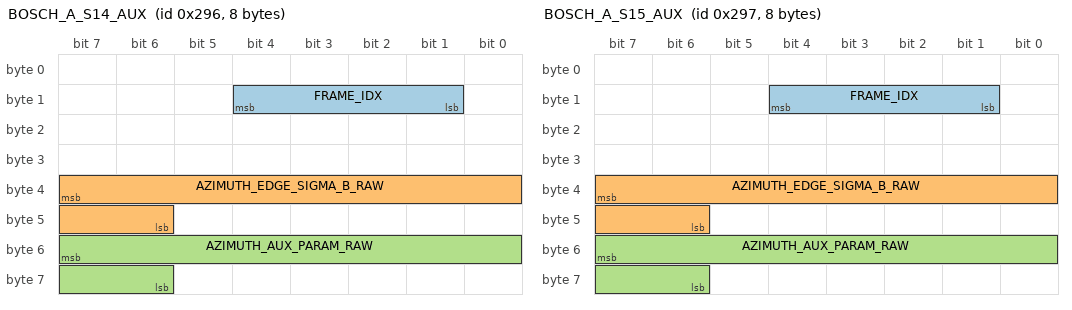
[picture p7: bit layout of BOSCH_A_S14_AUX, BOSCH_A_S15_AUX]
BO_ 662 BOSCH_A_S14_AUX: 8 RADAR
 SG_ FRAME_IDX : 12|4@0+ (1,0) [0|15] "" XXX
 SG_ AZIMUTH_EDGE_SIGMA_B_RAW : 39|10@0+ (1,0) [0|1023] "" XXX
 SG_ AZIMUTH_AUX_PARAM_RAW : 55|10@0+ (1,0) [0|1023] "" XXX

BO_ 764 BOSCH_A_S15_F0: 8 RADAR
 SG_ STATUS : 15|4@0+ (1,0) [0|15] "" XXX
 SG_ FRAME_IDX : 27|4@0+ (1,0) [0|15] "" XXX
 SG_ RANGE_RAW : 23|12@0+ (1,0) [0|4095] "" XXX
 SG_ RANGE : 23|12@0+ (0.05712,-3.0) [-3.0|231.7965] "m" XXX
 SG_ AZIMUTH_RAW : 39|11@0+ (1,0) [0|2047] "" XXX
 SG_ AZIMUTH_RAD : 39|11@0+ (0.00048828125,-0.5) [-0.5|0.49951171875] "rad" XXX
 SG_ AZIMUTH_DEG : 39|11@0+ (0.0279764548403722,-28.6478897565412) [-28.6478897565412|28.6199133017008] "deg" XXX

BO_ 765 BOSCH_A_S15_F1: 8 RADAR
 SG_ FRAME_IDX : 28|4@0+ (1,0) [0|15] "" XXX

BO_ 766 BOSCH_A_S15_F2: 8 RADAR
 SG_ FRAME_IDX : 11|4@0+ (1,0) [0|15] "" XXX
 SG_ LIFECYCLE_RAW : 7|12@0+ (1,0) [0|4095] "" XXX

BO_ 767 BOSCH_A_S15_F3: 8 RADAR
 SG_ AZIMUTH_EDGE_A_RAW : 7|11@0+ (1,0) [0|2047] "" XXX
 SG_ AZIMUTH_EDGE_A_RAD : 7|11@0+ (0.00048828125,-0.5) [-0.5|0.49951171875] "rad" XXX
 SG_ FRAME_IDX : 12|4@0+ (1,0) [0|15] "" XXX
 SG_ AZIMUTH_EDGE_B_RAW : 23|11@0+ (1,0) [0|2047] "" XXX
 SG_ AZIMUTH_EDGE_B_RAD : 23|11@0+ (0.00048828125,-0.5) [-0.5|0.49951171875] "rad" XXX
 SG_ AZIMUTH_EDGE_SIGMA_A_RAW : 39|10@0+ (1,0) [0|1023] "" XXX
 SG_ TRACK_ID : 55|8@0+ (1,0) [0|255] "" XXX

BO_ 663 BOSCH_A_S15_AUX: 8 RADAR
 SG_ FRAME_IDX : 12|4@0+ (1,0) [0|15] "" XXX
 SG_ AZIMUTH_EDGE_SIGMA_B_RAW : 39|10@0+ (1,0) [0|1023] "" XXX
 SG_ AZIMUTH_AUX_PARAM_RAW : 55|10@0+ (1,0) [0|1023] "" XXX

CM_ BO_ 640 "Slot 0 frame 0 (range/status/azimuth/frame-index). 0x280.";
CM_ BO_ 641 "Slot 0 frame 1 (frame-index only, core contract). 0x281.";
CM_ BO_ 642 "Slot 0 frame 2 (lifecycle/frame-index). 0x282.";
CM_ BO_ 643 "Slot 0 frame 3 (frame-index only, core contract). 0x283.";
CM_ BO_ 712 "Slot 0 auxiliary frame (enrichment only, never gates validity). 0x2C8.";
CM_ BO_ 644 "Slot 1 frame 0 (range/status/azimuth/frame-index). 0x284.";
CM_ BO_ 645 "Slot 1 frame 1 (frame-index only, core contract). 0x285.";
CM_ BO_ 646 "Slot 1 frame 2 (lifecycle/frame-index). 0x286.";
CM_ BO_ 647 "Slot 1 frame 3 (frame-index only, core contract). 0x287.";
CM_ BO_ 713 "Slot 1 auxiliary frame (enrichment only, never gates validity). 0x2C9.";
CM_ BO_ 648 "Slot 2 frame 0 (range/status/azimuth/frame-index). 0x288.";
CM_ BO_ 649 "Slot 2 frame 1 (frame-index only, core contract). 0x289.";
CM_ BO_ 650 "Slot 2 frame 2 (lifecycle/frame-index). 0x28A.";
CM_ BO_ 651 "Slot 2 frame 3 (frame-index only, core contract). 0x28B.";
CM_ BO_ 714 "Slot 2 auxiliary frame (enrichment only, never gates validity). 0x2CA.";
CM_ BO_ 652 "Slot 3 frame 0 (range/status/azimuth/frame-index). 0x28C.";
CM_ BO_ 653 "Slot 3 frame 1 (frame-index only, core contract). 0x28D.";
CM_ BO_ 654 "Slot 3 frame 2 (lifecycle/frame-index). 0x28E.";
CM_ BO_ 655 "Slot 3 frame 3 (frame-index only, core contract). 0x28F.";
CM_ BO_ 715 "Slot 3 auxiliary frame (enrichment only, never gates validity). 0x2CB.";
CM_ BO_ 720 "Slot 4 frame 0 (range/status/azimuth/frame-index). 0x2D0.";
CM_ BO_ 721 "Slot 4 frame 1 (frame-index only, core contract). 0x2D1.";
CM_ BO_ 722 "Slot 4 frame 2 (lifecycle/frame-index). 0x2D2.";
CM_ BO_ 723 "Slot 4 frame 3 (frame-index only, core contract). 0x2D3.";
CM_ BO_ 716 "Slot 4 auxiliary frame (enrichment only, never gates validity). 0x2CC.";
CM_ BO_ 724 "Slot 5 frame 0 (range/status/azimuth/frame-index). 0x2D4.";
CM_ BO_ 725 "Slot 5 frame 1 (frame-index only, core contract). 0x2D5.";
CM_ BO_ 726 "Slot 5 frame 2 (lifecycle/frame-index). 0x2D6.";
CM_ BO_ 727 "Slot 5 frame 3 (frame-index only, core contract). 0x2D7.";
CM_ BO_ 717 "Slot 5 auxiliary frame (enrichment only, never gates validity). 0x2CD.";
CM_ BO_ 728 "Slot 6 frame 0 (range/status/azimuth/frame-index). 0x2D8.";
CM_ BO_ 729 "Slot 6 frame 1 (frame-index only, core contract). 0x2D9.";
CM_ BO_ 730 "Slot 6 frame 2 (lifecycle/frame-index). 0x2DA.";
CM_ BO_ 731 "Slot 6 frame 3 (frame-index only, core contract). 0x2DB.";
CM_ BO_ 718 "Slot 6 auxiliary frame (enrichment only, never gates validity). 0x2CE.";
CM_ BO_ 732 "Slot 7 frame 0 (range/status/azimuth/frame-index). 0x2DC.";
CM_ BO_ 733 "Slot 7 frame 1 (frame-index only, core contract). 0x2DD.";
CM_ BO_ 734 "Slot 7 frame 2 (lifecycle/frame-index). 0x2DE.";
CM_ BO_ 735 "Slot 7 frame 3 (frame-index only, core contract). 0x2DF.";
CM_ BO_ 719 "Slot 7 auxiliary frame (enrichment only, never gates validity). 0x2CF.";
CM_ BO_ 736 "Slot 8 frame 0 (range/status/azimuth/frame-index). 0x2E0.";
CM_ BO_ 737 "Slot 8 frame 1 (frame-index only, core contract). 0x2E1.";
CM_ BO_ 738 "Slot 8 frame 2 (lifecycle/frame-index). 0x2E2.";
CM_ BO_ 739 "Slot 8 frame 3 (frame-index only, core contract). 0x2E3.";
CM_ BO_ 656 "Slot 8 auxiliary frame (enrichment only, never gates validity). 0x290.";
CM_ BO_ 740 "Slot 9 frame 0 (range/status/azimuth/frame-index). 0x2E4.";
CM_ BO_ 741 "Slot 9 frame 1 (frame-index only, core contract). 0x2E5.";
CM_ BO_ 742 "Slot 9 frame 2 (lifecycle/frame-index). 0x2E6.";
CM_ BO_ 743 "Slot 9 frame 3 (frame-index only, core contract). 0x2E7.";
CM_ BO_ 657 "Slot 9 auxiliary frame (enrichment only, never gates validity). 0x291.";
CM_ BO_ 744 "Slot 10 frame 0 (range/status/azimuth/frame-index). 0x2E8.";
CM_ BO_ 745 "Slot 10 frame 1 (frame-index only, core contract). 0x2E9.";
CM_ BO_ 746 "Slot 10 frame 2 (lifecycle/frame-index). 0x2EA.";
CM_ BO_ 747 "Slot 10 frame 3 (frame-index only, core contract). 0x2EB.";
CM_ BO_ 658 "Slot 10 auxiliary frame (enrichment only, never gates validity). 0x292.";
CM_ BO_ 748 "Slot 11 frame 0 (range/status/azimuth/frame-index). 0x2EC.";
CM_ BO_ 749 "Slot 11 frame 1 (frame-index only, core contract). 0x2ED.";
CM_ BO_ 750 "Slot 11 frame 2 (lifecycle/frame-index). 0x2EE.";
CM_ BO_ 751 "Slot 11 frame 3 (frame-index only, core contract). 0x2EF.";
CM_ BO_ 659 "Slot 11 auxiliary frame (enrichment only, never gates validity). 0x293.";
CM_ BO_ 752 "Slot 12 frame 0 (range/status/azimuth/frame-index). 0x2F0.";
CM_ BO_ 753 "Slot 12 frame 1 (frame-index only, core contract). 0x2F1.";
CM_ BO_ 754 "Slot 12 frame 2 (lifecycle/frame-index). 0x2F2.";
CM_ BO_ 755 "Slot 12 frame 3 (frame-index only, core contract). 0x2F3.";
CM_ BO_ 660 "Slot 12 auxiliary frame (enrichment only, never gates validity). 0x294.";
CM_ BO_ 756 "Slot 13 frame 0 (range/status/azimuth/frame-index). 0x2F4.";
CM_ BO_ 757 "Slot 13 frame 1 (frame-index only, core contract). 0x2F5.";
CM_ BO_ 758 "Slot 13 frame 2 (lifecycle/frame-index). 0x2F6.";
CM_ BO_ 759 "Slot 13 frame 3 (frame-index only, core contract). 0x2F7.";
CM_ BO_ 661 "Slot 13 auxiliary frame (enrichment only, never gates validity). 0x295.";
CM_ BO_ 760 "Slot 14 frame 0 (range/status/azimuth/frame-index). 0x2F8.";
CM_ BO_ 761 "Slot 14 frame 1 (frame-index only, core contract). 0x2F9.";
CM_ BO_ 762 "Slot 14 frame 2 (lifecycle/frame-index). 0x2FA.";
CM_ BO_ 763 "Slot 14 frame 3 (frame-index only, core contract). 0x2FB.";
CM_ BO_ 662 "Slot 14 auxiliary frame (enrichment only, never gates validity). 0x296.";
CM_ BO_ 764 "Slot 15 frame 0 (range/status/azimuth/frame-index). 0x2FC.";
CM_ BO_ 765 "Slot 15 frame 1 (frame-index only, core contract). 0x2FD.";
CM_ BO_ 766 "Slot 15 frame 2 (lifecycle/frame-index). 0x2FE.";
CM_ BO_ 767 "Slot 15 frame 3 (frame-index only, core contract). 0x2FF.";
CM_ BO_ 663 "Slot 15 auxiliary frame (enrichment only, never gates validity). 0x297.";
